# DA14681 register map
Vendor: Dialog; Series: DA14681; File version: 1.2
CPU: CM0 r1p0, little endian, MPU, FPU, 3 interrupt priority bits
Registers are 16-bit, read-write, reset 0x0 unless marked. A register's access mark holds for its fields unless they carry their own. Offsets are from the block's base; [hi:lo] are bit positions.

## SysTick — Cortex M0 SysTick registers
Base 0xE000E010
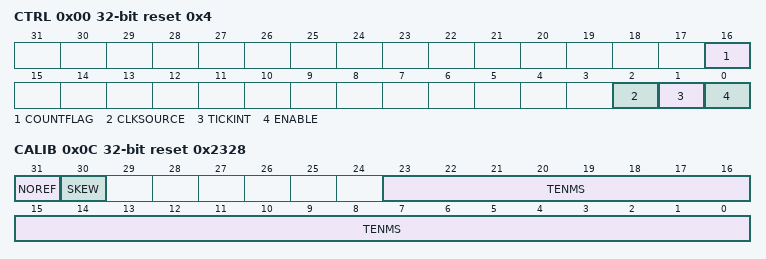
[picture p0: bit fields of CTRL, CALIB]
0x00 CTRL 32-bit reset 0x4 — SysTick Control and Status register
  [16] COUNTFLAG — Timer counted to 0 since last time this was read
  [2] CLKSOURCE — Clock source selection
  [1] TICKINT — SysTick exception request enable
  [0] ENABLE — SysTick Counter enable
0x04 LOAD 32-bit — SysTick Reload value register
  [23:0] RELOAD — RELOAD[23:0] bits (Reload value)
0x08 VAL 32-bit — SysTick Current value register
  [23:0] CURRENT — CURRENT[23:0] bits (Current counter value)
0x0C CALIB 32-bit ro reset 0x2328 — SysTick Calibration value register
  [31] NOREF — Indicates that a separate reference clock is provided
  [30] SKEW — Indicates whether the TENMS value is exact
  [23:0] TENMS — TENMS[23:0] bits (Calibration value)

## CHIP_VERSION — CHIP_VERSION registers
Base 0x50003200
0x00 CHIP_ID1_REG 8-bit reset 0x36 — Chip identification register 1.
  [7:0] CHIP_ID1 ro — First character of device type "680" in ASCII.
0x01 CHIP_ID2_REG 8-bit reset 0x38 — Chip identification register 2.
  [7:0] CHIP_ID2 ro — Second character of device type "680" in ASCII.
0x02 CHIP_ID3_REG 8-bit reset 0x30 — Chip identification register 3.
  [7:0] CHIP_ID3 ro — Third character of device type "680" in ASCII.
0x03 CHIP_SWC_REG 8-bit — Software compatibility register.
  [3:0] CHIP_SWC ro — SoftWare Compatibility code. Integer (default = 0) which is incremented if a silicon change has impact on the CPU Firmware. Can be used by software developers to write silicon revision dependent code.
0x04 CHIP_REVISION_REG 8-bit reset 0x42 — Chip revision register.
  [7:0] REVISION_ID ro — Chip version, corresponds with type number in ASCII. 0x41 = 'A', 0x42 = 'B'

## CRG_PER — CRG_PER registers
Base 0x50001C00
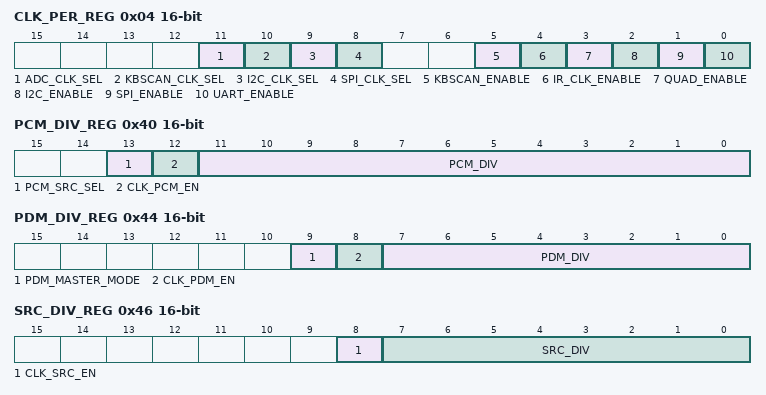
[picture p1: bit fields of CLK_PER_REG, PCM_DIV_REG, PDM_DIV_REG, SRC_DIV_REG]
0x04 CLK_PER_REG — Peripheral divider register
  [11] ADC_CLK_SEL — Selects the clock source 1 = DIV1 clock 0 = DIVN clock
  [10] KBSCAN_CLK_SEL — Selects the clock source 1 = DIV1 clock 0 = DIVN clock
  [9] I2C_CLK_SEL — Selects the clock source 1 = DIV1 clock 0 = DIVN clock
  [8] SPI_CLK_SEL — Selects the clock source 1 = DIV1 clock 0 = DIVN clock
  [5] KBSCAN_ENABLE — Enables the clock
  [4] IR_CLK_ENABLE — Enables the clock
  [3] QUAD_ENABLE — Enables the clock
  [2] I2C_ENABLE — Enables the clock
  [1] SPI_ENABLE — Enables the clock
  [0] UART_ENABLE — Enables the clock
0x40 PCM_DIV_REG — PCM divider and enables
  [13] PCM_SRC_SEL — Selects the clock source 1 = DIV1 clock 0 = DIVN clock
  [12] CLK_PCM_EN — Enable for the internally generated PCM clock The PCM_DIV must be set before or together with CLK_PCM_EN.
  [11:0] PCM_DIV — PCM clock divider
0x42 PCM_FDIV_REG — PCM fractional division register
  [15:0] PCM_FDIV — These bits define the fractional division part of the PCM clock. The left most '1' defines the denominator, the number of '1' bits define the numerator. E.g. 0x0110 means 2/9, with a distribution of 1.0001.0000 0xfeee means 13/16, with a distribution of 1111.1110.1110.1110
0x44 PDM_DIV_REG — PDM divider and enables
  [9] PDM_MASTER_MODE — Master mode selection 0: slave mode 1: master mode
  [8] CLK_PDM_EN — Enable for the internally generated PDM clock The PDM_DIV must be set before or together with CLK_PDM_EN.
  [7:0] PDM_DIV — PDM clock divider
0x46 SRC_DIV_REG — SRC divider and enables
  [8] CLK_SRC_EN — Enable for the internally generated SRC clock The SRC_DIV must be set before or together with CLK_SRC_EN.
  [7:0] SRC_DIV — SRC clock divider
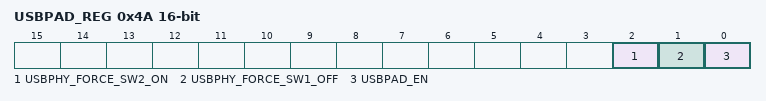
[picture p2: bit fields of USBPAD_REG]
0x4A USBPAD_REG — USB pads control register
  [2] USBPHY_FORCE_SW2_ON — 0: Pull up resistor SW2 is controlled by the USB controller. It is off when the USB is not enabled. 1: Force the pull up resistor on USBP to be 2.3Kohm
  [1] USBPHY_FORCE_SW1_OFF — 0: Pull up resistor SW1 is controlled by the USB controller. It is off when the USB is not enabled. 1: Force the pull up resistor on USBP to be switched off.
  [0] USBPAD_EN — 0: The power for the USB PHY and USB pads is switched on when the USB is enabled. 1: The power for the USB PHY and USB pads is forced on.
